# FM33G0XX register map
File version: 1.0
CPU: SC000 r1p0, little endian, no MPU, no FPU, 3 interrupt priority bits
Registers are 32-bit, read-write, reset 0x0 unless marked. A register's access mark holds for its fields unless they carry their own. Offsets are from the block's base; [hi:lo] are bit positions.

## RTC — RTC Registers
Base 0x40011000
0x00 RTCWE — RTC WRITE PROTECT REGISTER
  [0] RTCWE
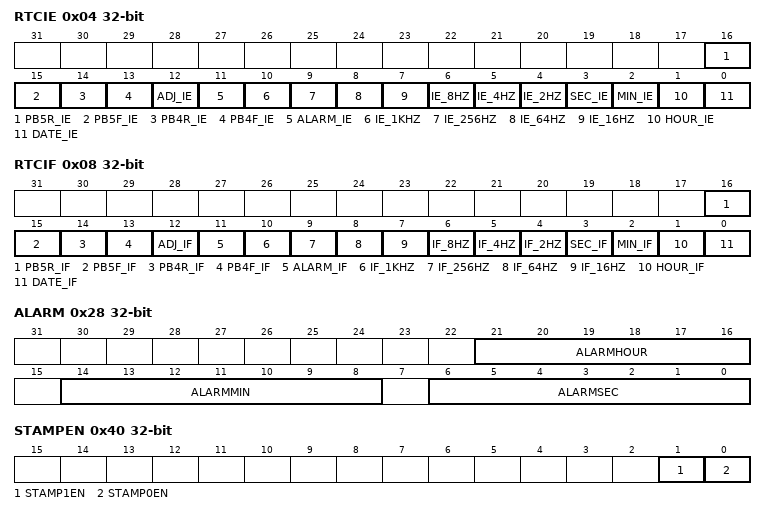
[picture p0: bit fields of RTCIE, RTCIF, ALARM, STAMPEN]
0x04 RTCIE
  [16] PB5R_IE, [15] PB5F_IE, [14] PB4R_IE, [13] PB4F_IE, [12] ADJ_IE, [11] ALARM_IE, [10] IE_1KHZ, [9] IE_256HZ, [8] IE_64HZ, [7] IE_16HZ, [6] IE_8HZ, [5] IE_4HZ, [4] IE_2HZ, [3] SEC_IE, [2] MIN_IE, [1] HOUR_IE, [0] DATE_IE
0x08 RTCIF
  [16] PB5R_IF, [15] PB5F_IF, [14] PB4R_IF, [13] PB4F_IF, [12] ADJ_IF, [11] ALARM_IF, [10] IF_1KHZ, [9] IF_256HZ, [8] IF_64HZ, [7] IF_16HZ, [6] IF_8HZ, [5] IF_4HZ, [4] IF_2HZ, [3] SEC_IF, [2] MIN_IF, [1] HOUR_IF, [0] DATE_IF
0x0C BCDSEC — SECOND REGISTER IN BCD
  [6:0] BCDSEC — SECOND IN BCD
0x10 BCDMIN — MINUTE REGISTER IN BCD
  [6:0] BCDMIN — MINUTE IN BCD
0x14 BCDHOUR — HOUR REGISTER IN BCD
  [5:0] BCDHOUR — HOUR IN BCD
0x18 BCDDATE — DATE REGISTER IN BCD
  [5:0] BCDDATE — DATE IN BCD
0x1C BCDWEEK — WEEK REGISTER IN BCD
  [2:0] BCDWEEK — WEEK IN BCD
0x20 BCDMONTH — MONTH REGISTER IN BCD
  [4:0] BCDMONTH — MONTH IN BCD
0x24 BCDYEAR — YEAR REGISTER IN BCD
  [7:0] BCDYEAR — YEAR IN BCD
0x28 ALARM — ALARM SETTING REGISTER
  [21:16] ALARMHOUR — ALARM HOUR SETTING
  [14:8] ALARMMIN — ALARM MINUTE SETTING
  [6:0] ALARMSEC — ALARM SECOND SETTING
0x2C FSEL — FREQ SIGNAL OUTPUT SELECT
  [3:0] FSEL
    0=SEC_SQUARE (ONE SECONG SQUARE WAVE FROM PLL); 1=SEC_80MS (ONE SECONG WAVE FROM PLL); 2=SEC_CARRY (SECOND CARRY SIGNAL); 3=MIN_CARRY (MINUTE CARRY SIGNAL); 4=HOUR_CARRY (HOUR CARRY SIGNAL); 5=DATE_CARRY (DATE CARRY SIGNAL); 6=ALARM_SIG (ALARM SIGNAL); 7=128SEC (128 SECOND SQUARE SIGNAL); 8=REV_SEC_80MS (REVERSE SEC_80MS); 9=REV_SEC_CARRY (REVERSE SEC_CARRY); 10=REV_MIN_CARRY (REVERSE MINUTE CARRY SIGNAL); 11=REV_HOUR_CARRY (REVERSE HOUR CARRY SIGNAL); 12=REV_DATE_CARRY (REVERSE DATE CARRY SIGNAL); 13=REV_ALARM (REVERSE ALARM SIGNAL); 14=REV_SEC_SQUARE (REVERSE SEC_SQUARE SIGNAL); 15=INNER_SEC (INNER SECOND SIGNAL)
0x30 ADJUST — LTBC ADJUST register
  [10:0] ADJUST — LTBC ADJUST
0x34 ADSIGN — LTBC ADJUST SIGN REGISTER
  [0] ADSIGN — LTBC ADJUST SIGN
0x38 PR1SEN — VIRTUAL TUNING register
  [0] PR1SEN — VIRTUAL TUNING enable
0x3C MSECCNT — MS COUNTER register
  [7:0] MSECCNT — MS COUNTER
0x40 STAMPEN — STAMP Enable register
  [1] STAMP1EN — STAMP1 enable
  [0] STAMP0EN — STAMP0 enable
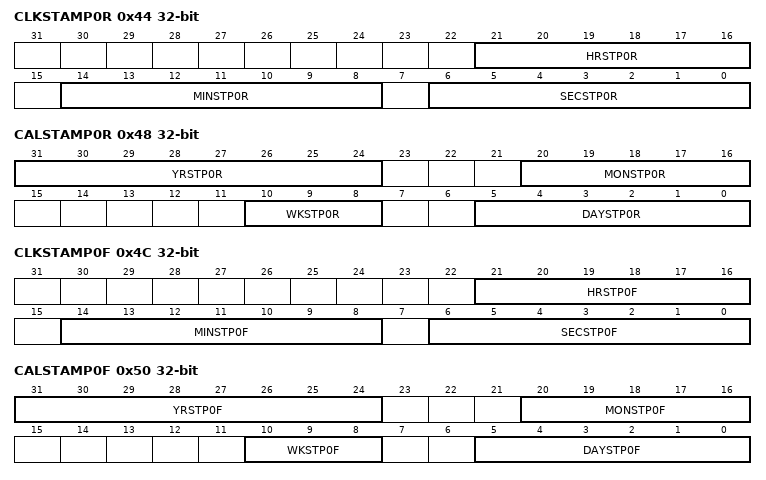
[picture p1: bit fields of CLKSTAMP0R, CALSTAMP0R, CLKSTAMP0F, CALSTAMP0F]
0x44 CLKSTAMP0R — STAMP0 STORAGE AT RISING EDGE register
  [21:16] HRSTP0R, [14:8] MINSTP0R, [6:0] SECSTP0R
0x48 CALSTAMP0R — STAMP0 STORAGE AT RISING EDGE register
  [31:24] YRSTP0R, [20:16] MONSTP0R, [10:8] WKSTP0R, [5:0] DAYSTP0R
0x4C CLKSTAMP0F — STAMP0 STORAGE AT FALLING EDGE register
  [21:16] HRSTP0F, [14:8] MINSTP0F, [6:0] SECSTP0F
0x50 CALSTAMP0F — STAMP0 STORAGE AT FALLING EDGE register
  [31:24] YRSTP0F, [20:16] MONSTP0F, [10:8] WKSTP0F, [5:0] DAYSTP0F
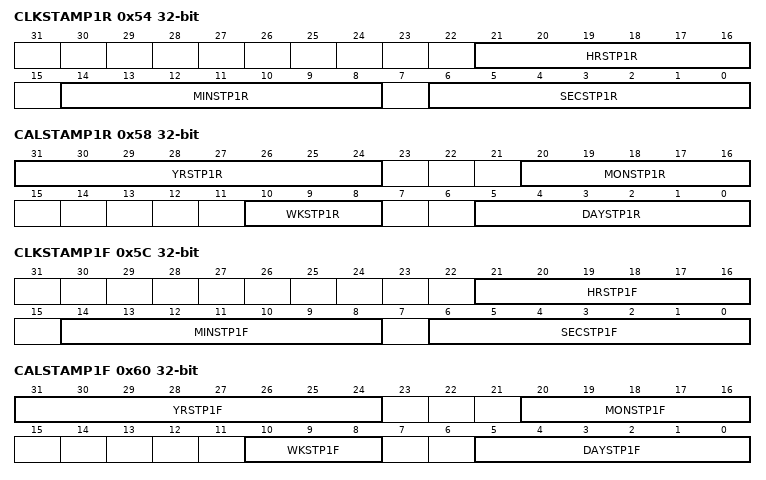
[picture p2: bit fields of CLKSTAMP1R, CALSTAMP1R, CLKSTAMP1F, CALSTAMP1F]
0x54 CLKSTAMP1R — STAMP1 STORAGE AT RISING EDGE register
  [21:16] HRSTP1R, [14:8] MINSTP1R, [6:0] SECSTP1R
0x58 CALSTAMP1R — STAMP1 STORAGE AT RISING EDGE register
  [31:24] YRSTP1R, [20:16] MONSTP1R, [10:8] WKSTP1R, [5:0] DAYSTP1R
0x5C CLKSTAMP1F — STAMP1 STORAGE AT FALLING EDGE register
  [21:16] HRSTP1F, [14:8] MINSTP1F, [6:0] SECSTP1F
0x60 CALSTAMP1F — STAMP1 STORAGE AT FALLING EDGE register
  [31:24] YRSTP1F, [20:16] MONSTP1F, [10:8] WKSTP1F, [5:0] DAYSTP1F
0x64 AUTOCAL — AUTO CAL ENABLE register
  [0] ACALEN — AUTO CAL ENABLE
0x68 ADOFFSET — AUTO CAL OFFSET register
  [10:0] ADOFFSET — AUTO CAL OFFSET
0x6C CALSTEP — AUTO CAL STEP register
  [0] CALSTEP — AUTO CAL STEP
    0=0_238ppm; 1=0_119ppm
0x70 AUCALBUSY — AUTO CAL BUSY register
  [0] AUCALBUSY — AUTO CAL BUSY
0x74 ADJCNT — AUTO CAL CIRCLE COUNT register
  [7:0] ADJCNT
0x78 AUADJUST — AUTO CAL DATA register
  [12:0] AUADJUST — AUTO CAL DATA

## IWDT
Base 0x40011400
0x00 IWDTSERV wo — IWDT SERVER
0x04 IWDTCFG — IWDT CONFIG REGISTER
  [1:0] IWDTOVP — IWDT overflow period setting
    0=125MS; 1=500MS; 2=2S; 3=8S
0x08 IWDTCNT ro — iwdt counter register
  [17:0] IWDTCNT rw — IWDTCNT counter
